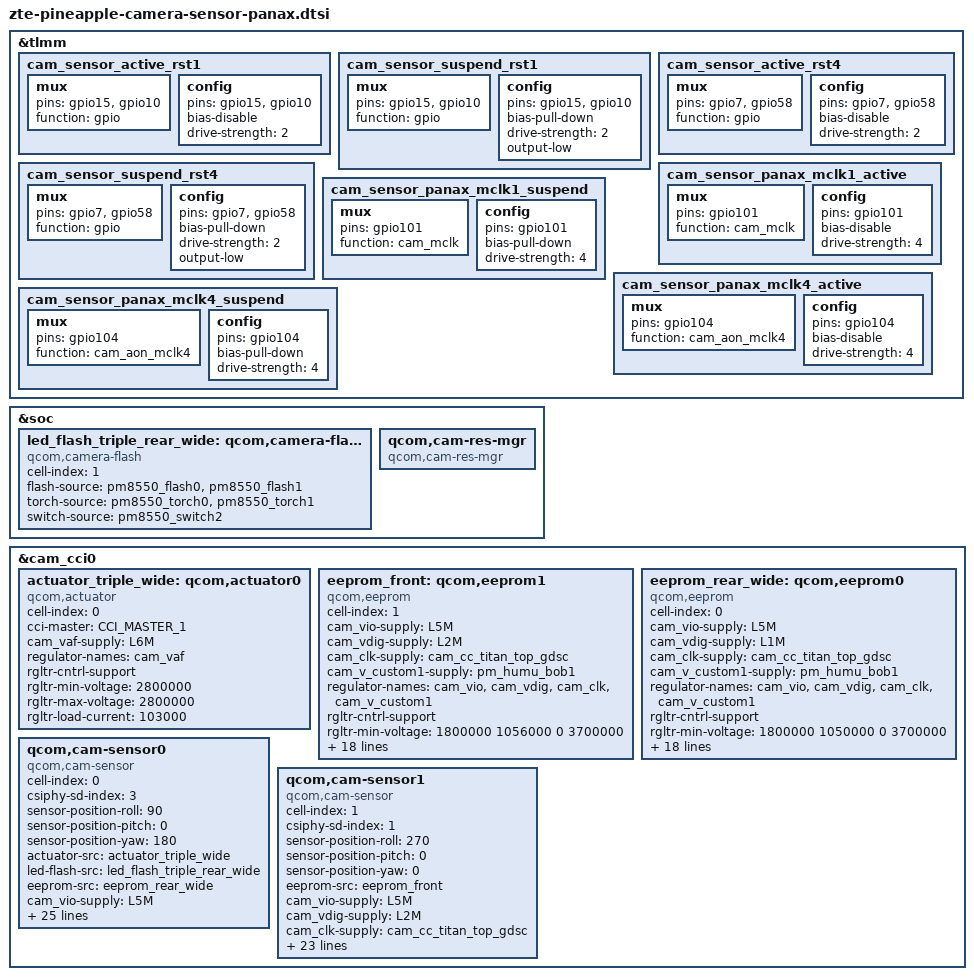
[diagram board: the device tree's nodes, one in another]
#include <dt-bindings/msm-camera.h>
&tlmm {
	cam_sensor_active_rst1: cam_sensor_active_rst1 {
		/* RESET 1 */
		mux {
			pins = "gpio15", "gpio10";
			function = "gpio";
		};

		config {
			pins = "gpio15", "gpio10";
			bias-disable; /* No PULL */
			drive-strength = <2>; /* 2 MA */
		};
	};

	cam_sensor_suspend_rst1: cam_sensor_suspend_rst1 {
		/* RESET 1 */
		mux {
			pins = "gpio15", "gpio10";
			function = "gpio";
		};

		config {
			pins = "gpio15", "gpio10";
			bias-pull-down; /* PULL DOWN */
			drive-strength = <2>; /* 2 MA */
			output-low;
		};
	};
	
	cam_sensor_active_rst4: cam_sensor_active_rst4 {
		/* RESET 1 */
		mux {
			pins = "gpio7", "gpio58";
			function = "gpio";
		};

		config {
			pins = "gpio7", "gpio58";
			bias-disable; /* No PULL */
			drive-strength = <2>; /* 2 MA */
		};
	};

	cam_sensor_suspend_rst4: cam_sensor_suspend_rst4 {
		/* RESET 1 */
		mux {
			pins = "gpio7", "gpio58";
			function = "gpio";
		};

		config {
			pins = "gpio7", "gpio58";
			bias-pull-down; /* PULL DOWN */
			drive-strength = <2>; /* 2 MA */
			output-low;
		};
	};

	cam_sensor_panax_mclk1_active: cam_sensor_panax_mclk1_active {
		/* MCLK1 */
		mux {
			pins = "gpio101";
			function = "cam_mclk";
		};

		config {
			pins = "gpio101";
			bias-disable; /* No PULL */
			drive-strength = <4>; /* 2 MA */
		};
	};

	cam_sensor_panax_mclk1_suspend: cam_sensor_panax_mclk1_suspend {
		/* MCLK1 */
		mux {
			pins = "gpio101";
			function = "cam_mclk";
		};

		config {
			pins = "gpio101";
			bias-pull-down; /* PULL DOWN */
			drive-strength = <4>; /* 2 MA */
		};
	};

	cam_sensor_panax_mclk4_active: cam_sensor_panax_mclk4_active {
		/* MCLK4 */
		mux {
			pins = "gpio104";
			function = "cam_aon_mclk4";
		};

		config {
			pins = "gpio104";
			bias-disable; /* No PULL */
			drive-strength = <4>; /* 2 MA */
		};
	};

	cam_sensor_panax_mclk4_suspend: cam_sensor_panax_mclk4_suspend {
		/* MCLK4 */
		mux {
			pins = "gpio104";
			function = "cam_aon_mclk4";
		};

		config {
			pins = "gpio104";
			bias-pull-down; /* PULL DOWN */
			drive-strength = <4>; /* 2 MA */
		};
	};
};

&soc {
	led_flash_triple_rear_wide: qcom,camera-flash1 {
		cell-index = <1>;
		compatible = "qcom,camera-flash";
		flash-source = <&pm8550_flash0 &pm8550_flash1>;
		torch-source = <&pm8550_torch0 &pm8550_torch1>;
		switch-source = <&pm8550_switch2>;
		status = "ok";
	};

	qcom,cam-res-mgr {
		compatible = "qcom,cam-res-mgr";
		status = "ok";
	};
};

&cam_cci0 {
	actuator_triple_wide: qcom,actuator0 {
		cell-index = <0>;
		compatible = "qcom,actuator";
		cci-master = <CCI_MASTER_1>;
		cam_vaf-supply = <&L6M>;
		regulator-names = "cam_vaf";
		rgltr-cntrl-support;
		rgltr-min-voltage = <2800000>;
		rgltr-max-voltage = <2800000>;
		rgltr-load-current = <103000>;
	};

	eeprom_front: qcom,eeprom1 {
		cell-index = <1>;
		compatible = "qcom,eeprom";
		cam_vio-supply = <&L5M>;
		cam_vdig-supply = <&L2M>;
		cam_clk-supply = <&cam_cc_titan_top_gdsc>;
		cam_v_custom1-supply = <&pm_humu_bob1>;
		regulator-names = "cam_vio", "cam_vdig", "cam_clk", "cam_v_custom1";
		rgltr-cntrl-support;
		rgltr-min-voltage = <1800000 1056000 0 3700000>;
		rgltr-max-voltage = <1800000 1056000 0 3700000>;
		rgltr-load-current = <10000 140000 0 3296000>;
		gpio-no-mux = <0>;
		pinctrl-names = "cam_default", "cam_suspend";
		pinctrl-0 = <&cam_sensor_panax_mclk4_active
				 &cam_sensor_active_rst4>;
		pinctrl-1 = <&cam_sensor_panax_mclk4_suspend
				 &cam_sensor_suspend_rst4>;
		gpios = <&tlmm 104 0>,
			<&tlmm 7 0>,
			<&tlmm 58 0>;
		gpio-reset = <1>;
		gpio-custom1 = <2>;
		gpio-req-tbl-num = <0 1 2>;
		gpio-req-tbl-flags = <1 0 0>;
		gpio-req-tbl-label = "CAMIF_MCLK4",
					"CAM_RESET4",
					"CAM_VANA4";
		cci-master = <CCI_MASTER_0>;
		clocks = <&camcc CAM_CC_MCLK4_CLK>;
		clock-names = "cam_clk";
		clock-cntl-level = "nominal";
		clock-rates = <24000000>;
		status = "ok";
	};

	eeprom_rear_wide: qcom,eeprom0 {
		cell-index = <0>;
		compatible = "qcom,eeprom";
		cam_vio-supply = <&L5M>;
		cam_vdig-supply = <&L1M>;
		cam_clk-supply = <&cam_cc_titan_top_gdsc>;
		cam_v_custom1-supply = <&pm_humu_bob1>;
		regulator-names = "cam_vio", "cam_vdig", "cam_clk", "cam_v_custom1";
		rgltr-cntrl-support;
		rgltr-min-voltage = <1800000 1050000 0 3700000>;
		rgltr-max-voltage = <1800000 1050000 0 3700000>;
		rgltr-load-current = <3500 300000 0 3296000>;
		gpio-no-mux = <0>;
		pinctrl-names = "cam_default", "cam_suspend";
		pinctrl-0 = <&cam_sensor_panax_mclk1_active
				 &cam_sensor_active_rst1>;
		pinctrl-1 = <&cam_sensor_panax_mclk1_suspend
				 &cam_sensor_suspend_rst1>;
		gpios = <&tlmm 101 0>,
			<&tlmm 15 0>,
			<&tlmm 10 0>;
		gpio-reset = <1>;
		gpio-custom1 = <2>;
		gpio-req-tbl-num = <0 1 2>;
		gpio-req-tbl-flags = <1 0 0>;
		gpio-req-tbl-label = "CAMIF_MCLK1",
					"CAM_RESET1",
					"CAM_VANA1";
		cci-master = <CCI_MASTER_1>;
		clocks = <&camcc CAM_CC_MCLK1_CLK>;
		clock-names = "cam_clk";
		clock-cntl-level = "nominal";
		clock-rates = <24000000>;
		status = "ok";
	};


//main
	qcom,cam-sensor0 {
		cell-index = <0>;
		compatible = "qcom,cam-sensor";
		csiphy-sd-index = <3>;
		sensor-position-roll = <90>;
		sensor-position-pitch = <0>;
		sensor-position-yaw = <180>;
		actuator-src = <&actuator_triple_wide>;
		led-flash-src = <&led_flash_triple_rear_wide>;
		eeprom-src = <&eeprom_rear_wide>;
		cam_vio-supply = <&L5M>;
		cam_vdig-supply = <&L1M>;
		cam_clk-supply = <&cam_cc_titan_top_gdsc>;
		cam_v_custom1-supply = <&pm_humu_bob1>;
		regulator-names = "cam_vio", "cam_vdig", "cam_clk", "cam_v_custom1";
		rgltr-cntrl-support;
		rgltr-min-voltage = <1800000 1050000 0 3700000>;
		rgltr-max-voltage = <1800000 1050000 0 3700000>;
		rgltr-load-current = <3500 300000 0 3296000>;
		gpio-no-mux = <0>;
		pinctrl-names = "cam_default", "cam_suspend";
		pinctrl-0 = <&cam_sensor_panax_mclk1_active
				 &cam_sensor_active_rst1>;
		pinctrl-1 = <&cam_sensor_panax_mclk1_suspend
				 &cam_sensor_suspend_rst1>;
		gpios = <&tlmm 101 0>,
			<&tlmm 15 0>,
			<&tlmm 10 0>;
		gpio-reset = <1>;
		gpio-custom1 = <2>;
		gpio-req-tbl-num = <0 1 2>;
		gpio-req-tbl-flags = <1 0 0>;
		gpio-req-tbl-label = "CAMIF_MCLK1",
					"CAM_RESET1",
					"CAM_VANA1";
		cci-master = <CCI_MASTER_1>;
		clocks = <&camcc CAM_CC_MCLK1_CLK>;
		clock-names = "cam_clk";
		clock-cntl-level = "nominal";
		clock-rates = <24000000>;
		status = "ok";
	};

//front
	qcom,cam-sensor1 {
		cell-index = <1>;
		compatible = "qcom,cam-sensor";
		csiphy-sd-index = <1>;
		sensor-position-roll = <270>;
		sensor-position-pitch = <0>;
		sensor-position-yaw = <0>;
		eeprom-src = <&eeprom_front>;
		cam_vio-supply = <&L5M>;
		cam_vdig-supply = <&L2M>;
		cam_clk-supply = <&cam_cc_titan_top_gdsc>;
		cam_v_custom1-supply = <&pm_humu_bob1>;
		regulator-names = "cam_vio", "cam_vdig", "cam_clk", "cam_v_custom1";
		rgltr-cntrl-support;
		rgltr-min-voltage = <1800000 1056000 0 3700000>;
		rgltr-max-voltage = <1800000 1056000 0 3700000>;
		rgltr-load-current = <10000 140000 0 3296000>;
		gpio-no-mux = <0>;
		pinctrl-names = "cam_default", "cam_suspend";
		pinctrl-0 = <&cam_sensor_panax_mclk4_active
				 &cam_sensor_active_rst4>;
		pinctrl-1 = <&cam_sensor_panax_mclk4_suspend
				 &cam_sensor_suspend_rst4>;
		gpios = <&tlmm 104 0>,
			<&tlmm 7 0>,
			<&tlmm 58 0>;
		gpio-reset = <1>;
		gpio-custom1 = <2>;
		gpio-req-tbl-num = <0 1 2>;
		gpio-req-tbl-flags = <1 0 0>;
		gpio-req-tbl-label = "CAMIF_MCLK4",
					"CAM_RESET4",
					"CAM_VANA4";
		cci-master = <CCI_MASTER_0>;
		clocks = <&camcc CAM_CC_MCLK4_CLK>;
		clock-names = "cam_clk";
		clock-cntl-level = "nominal";
		clock-rates = <24000000>;
		status = "ok";
	};
};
